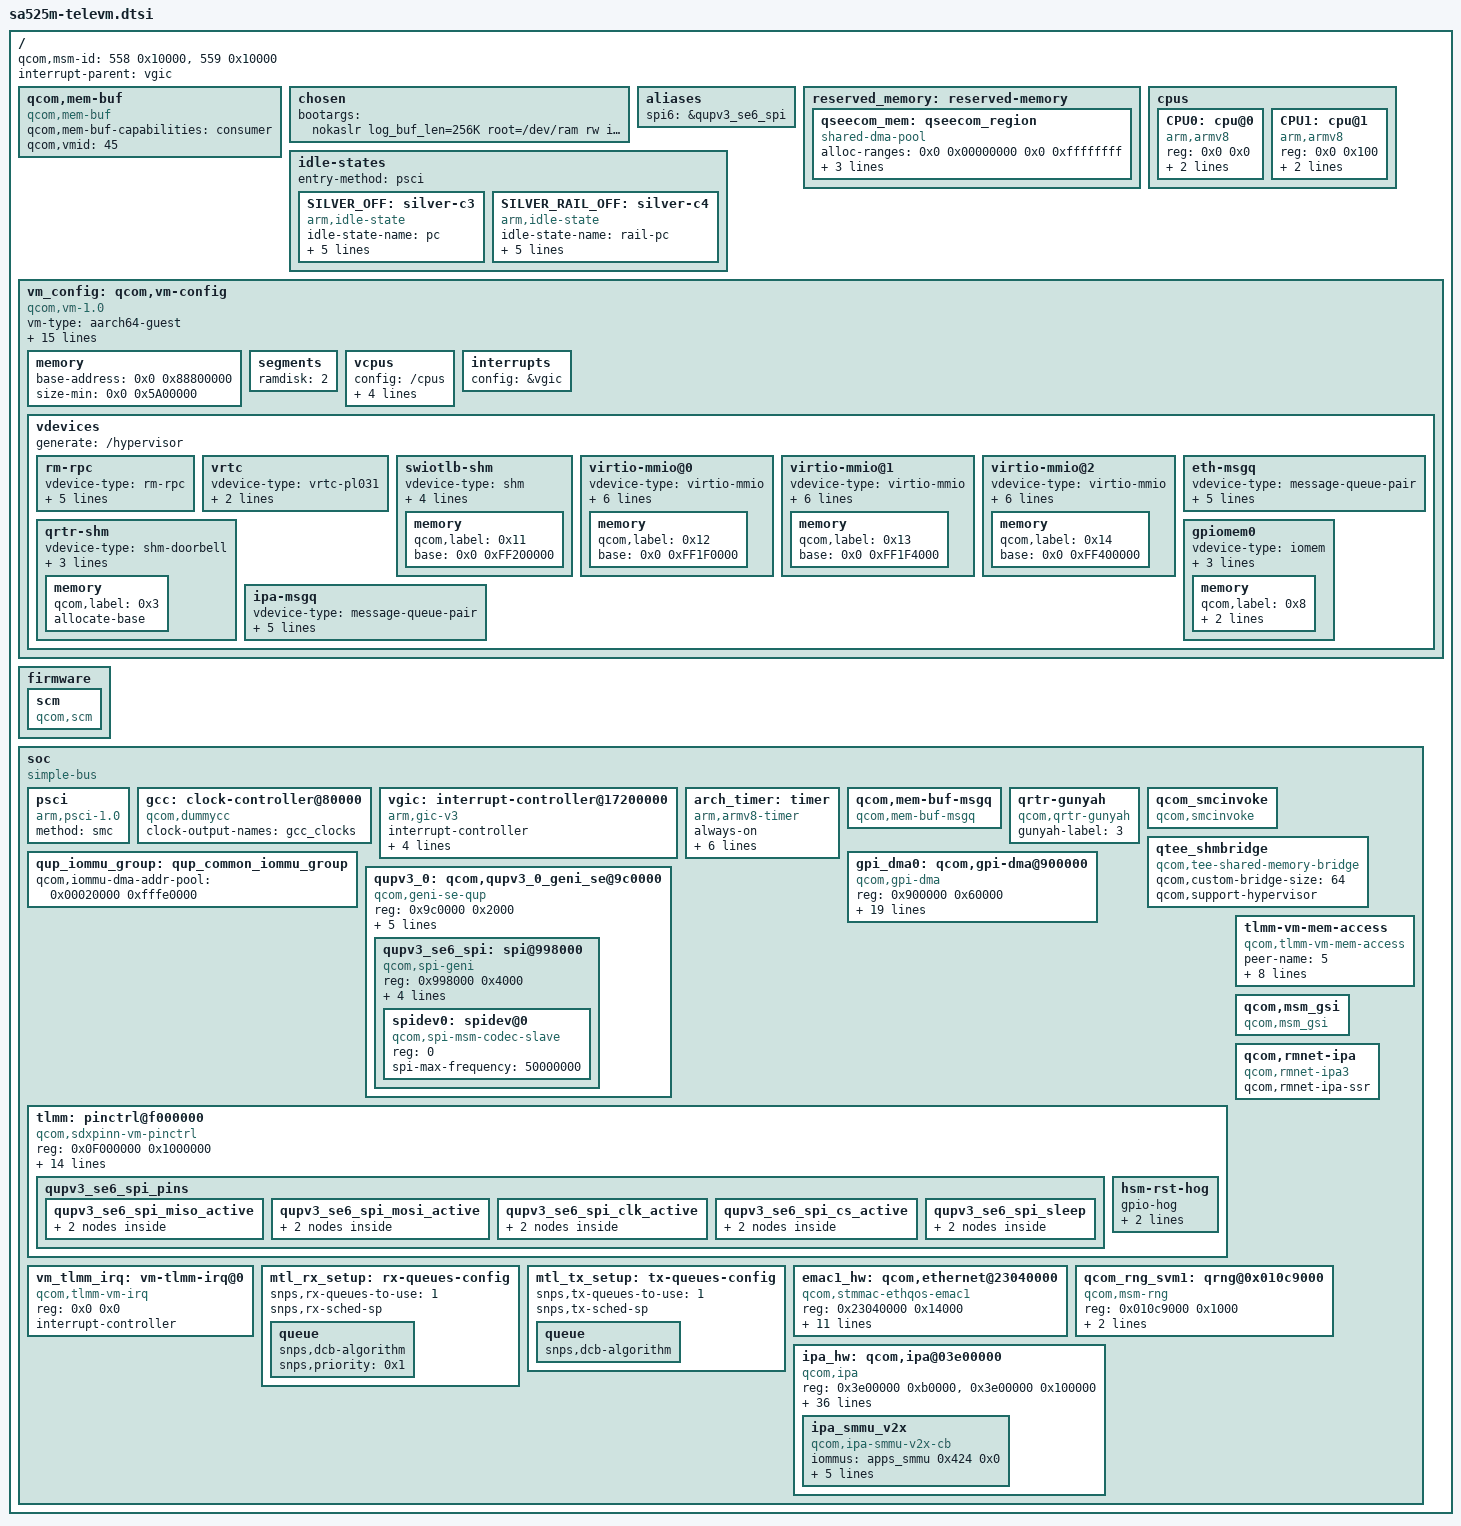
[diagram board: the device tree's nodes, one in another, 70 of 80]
#include <dt-bindings/interrupt-controller/arm-gic.h>
#include <dt-bindings/clock/qcom,gcc-sdxpinn.h>
#include <dt-bindings/clock/qcom,rpmh.h>

/ {
	#address-cells = <0x2>;
	#size-cells = <0x2>;
	qcom,msm-id = <558 0x10000>, <559 0x10000>;
	interrupt-parent = <&vgic>;

	qcom,mem-buf {
		compatible = "qcom,mem-buf";
		qcom,mem-buf-capabilities = "consumer";
		qcom,vmid = <45>;
	};

	chosen {
		 bootargs = "nokaslr log_buf_len=256K root=/dev/ram rw init=/init console=hvc0 loglevel=8";
	};

	aliases {
		spi6 = &qupv3_se6_spi;
	};

	reserved_memory: reserved-memory {
		#address-cells = <2>;
		#size-cells = <2>;
		ranges;
		qseecom_mem: qseecom_region {
			compatible = "shared-dma-pool";
			alloc-ranges = <0x0 0x00000000 0x0 0xffffffff>;
			reusable;
			alignment = <0x0 0x400000>;
			size = <0x0 0x400000>;
		};
	};

	cpus {
		#address-cells = <0x2>;
		#size-cells = <0x0>;

		CPU0: cpu@0 {
			compatible = "arm,armv8";
			reg = <0x0 0x0>;
			device_type = "cpu";
			enable-method = "psci";
			cpu-idle-states = <&SILVER_OFF &SILVER_RAIL_OFF>;
		};

		CPU1: cpu@1 {
			compatible = "arm,armv8";
			reg = <0x0 0x100>;
			device_type = "cpu";
			enable-method = "psci";
			cpu-idle-states = <&SILVER_OFF &SILVER_RAIL_OFF>;
		};

	};

	idle-states {
		entry-method = "psci";

		SILVER_OFF: silver-c3 { /* C3 */
			compatible = "arm,idle-state";
			idle-state-name = "pc";
			entry-latency-us = <235>;
			exit-latency-us = <428>;
			min-residency-us = <1774>;
			arm,psci-suspend-param = <0x40000003>;
			local-timer-stop;
		};

		SILVER_RAIL_OFF: silver-c4 { /* C4 */
			compatible = "arm,idle-state";
			idle-state-name = "rail-pc";
			entry-latency-us = <800>;
			exit-latency-us = <750>;
			min-residency-us = <4090>;
			arm,psci-suspend-param = <0x40000004>;
			local-timer-stop;
		};
	};

	vm_config: qcom,vm-config {
		compatible = "qcom,vm-1.0";
		vm-type = "aarch64-guest";
		boot-config = "fdt,unified";
		os-type = "linux";
		kernel-entry-segment = "kernel";
		kernel-entry-offset = <0x0 0x0>;
		vendor = "QTI";
		image-name = "qcom,televm";
		qcom,pasid = <0x0 0x1c>;
		qcom,qtee-config-info = "p=57,77,78,7C,8F,97,159,199,47E,7F1;";
		qcom,secdomain-ids = <45>;
		qcom,primary-vm-index = <0>;

		iomemory-ranges = <0x0 0x928000 0x0 0x928000 0x0 0x4000 0x0
				   0x0 0x998000 0x0 0x998000 0x0 0x4000 0x0
				   0x0 0x3e00000 0x0 0x3e00000 0x0 0x200000 0x0
				   0x0 0x23052000 0x0 0x23052000 0x0 0x1000 0x0
				   0x0 0x2304C000 0x0 0x2304C000 0x0 0x1000 0x0
				   0x0 0x0F1B7000 0x0 0x0F1B7000 0x0 0x2000 0x0
				   0x0 0x010c9000 0x0 0x010c9000 0x0 0x1000 0x0>;

		gic-irq-ranges = <245 245 // 213 DIR CONN HMMS /* PVM->SVM IRQ transfer */
				246 246 // 214 DIR CONN HMMS
				247 247 // 215 DIR CONN HMMS
				248 248 // 216 DIR CONN HMMS
				249 249 // 217 DIR CONN HMMS
				250 250 // 218 DIR CONN HMMS
				251 251 // 219 DIR CONN HMMS
				252 252 // 220 DIR CONN HMMS
				344 344 // 312 IPA
				350 350 // 318 IPA
				383 383 // 351 QUPV3 GSI IRQ
				432 432 // 400 MVM
				433 433 // 401 MVM
				436 436 // 404 MVM
				439 439 // 407 MVM
				483 483>;

		memory {
			#address-cells = <0x2>;
			#size-cells = <0x0>;
			base-address = <0x0 0x88800000>;
			size-min = <0x0 0x5A00000>; /* 90 MB */
		};

		segments {
			ramdisk = <2>; /* 8 MB */
		};

		vcpus {
			config = "/cpus";
			affinity = "proxy";
			affinity-map = <0x0 0x1>;
			sched-priority = <0>;       /* relative to PVM */
			sched-timeslice = <2000>;   /* in ms */
		};

		interrupts {
			config = &vgic;
		};

		vdevices {
			generate = "/hypervisor";
			rm-rpc {
				vdevice-type = "rm-rpc";
				generate = "/hypervisor/qcom,resource-mgr";
				console-dev;
				message-size = <0x000000f0>;
				queue-depth = <0x00000008>;
				qcom,label = <0x1>;
			};

			vrtc {
				vdevice-type = "vrtc-pl031";
				peer-default;
				allocate-base;
			};

			swiotlb-shm {
				vdevice-type = "shm";
				generate = "/swiotlb";
				push-compatible = "swiotlb";
				peer-default;
				dma_base = <0x0 0x10000>;
				memory {
					qcom,label = <0x11>;
					#address-cells = <0x2>;
					base = <0x0 0xFF200000>; /*2MB aligned*/

				};
			};

			virtio-mmio@0 {
				vdevice-type = "virtio-mmio";
				generate = "/virtio-mmio";
				peer-default;
				vqs-num = <0x1>;
				push-compatible = "virtio,mmio";
				dma-coherent;
				dma_base = <0x0 0x0>;
				memory {
					qcom,label = <0x12>;	//for systemrw.img
					#address-cells = <0x2>;
					base = <0x0 0xFF1F0000>;
				};
			};

			virtio-mmio@1 {
				vdevice-type = "virtio-mmio";
				generate = "/virtio-mmio";
				peer-default;
				vqs-num = <0x3>;
				push-compatible = "virtio,mmio";
				dma-coherent;
				dma_base = <0x0 0x4000>;
				memory {
					qcom,label = <0x13>;	//for net
					#address-cells = <0x2>;
					base = <0x0 0xFF1F4000>;
				};
			};

			virtio-mmio@2 {
				vdevice-type = "virtio-mmio";
				generate = "/virtio-mmio";
				peer-default;
				vqs-num = <0x2>;
				push-compatible = "virtio,mmio";
				dma-coherent;
				dma_base = <0x0 0x210000>;
				memory {
					qcom,label = <0x14>;	//for system.img
					#address-cells = <0x2>;
					base = <0x0 0xFF400000>;
				};
			};

			eth-msgq {
				vdevice-type = "message-queue-pair";
				generate = "/hypervisor/geth-msgq-pair";
				message-size = <0xf0>;
				queue-depth = <0x8>;
				peer-default;
				qcom,label = <0xB>;
			};

			qrtr-shm {
				vdevice-type = "shm-doorbell";
				generate = "/hypervisor/qrtr-shm";
				push-compatible = "qcom,qrtr-gunyah-gen";
				peer-default;
				memory {
					qcom,label = <0x3>;
					allocate-base;
				};
			};

			gpiomem0 {
				vdevice-type = "iomem";
				patch = "/soc/tlmm-vm-mem-access";
				push-compatible = "qcom,tlmm-vm-mem-access";
				peer-default;
				memory {
					qcom,label = <0x8>;
					qcom,mem-info-tag = <0x3>;
					allocate-base;
				};
			};

			ipa-msgq {
				vdevice-type = "message-queue-pair";
				generate = "/hypervisor/ipa-msgq-pair";
				message-size = <0xf0>;
				queue-depth = <0x8>;
				peer-default;
				qcom,label = <10>;
			};
		};
	};

	firmware: firmware {
		scm {
			compatible = "qcom,scm";
		};
	};

	soc: soc { };
};

&soc {
	#address-cells = <1>;
	#size-cells = <1>;
	ranges = <0 0 0 0xffffffff>;
	compatible = "simple-bus";

	psci {
		compatible = "arm,psci-1.0";
		method = "smc";
	};

	gcc: clock-controller@80000 {
		compatible = "qcom,dummycc";
		clock-output-names = "gcc_clocks";
		#clock-cells = <1>;
		#reset-cells = <1>;
	};

	vgic: interrupt-controller@17200000 {
		compatible = "arm,gic-v3";
		#interrupt-cells = <3>;
		interrupt-controller;
		#redistributor-regions = <1>;
		redistributor-stride = <0x0 0x20000>;
		reg = <0x17200000 0x10000>,/* GICD */
				<0x17260000 0x80000>;/* GICR * 4 */
		interrupts = <GIC_PPI 9 IRQ_TYPE_LEVEL_HIGH>;
	};

	arch_timer: timer {
		compatible = "arm,armv8-timer";
		always-on;
		interrupts = <GIC_PPI 13 (GIC_CPU_MASK_SIMPLE(8) | IRQ_TYPE_LEVEL_LOW)>,
			<GIC_PPI 14 (GIC_CPU_MASK_SIMPLE(8) | IRQ_TYPE_LEVEL_LOW)>,
			<GIC_PPI 11 (GIC_CPU_MASK_SIMPLE(8) | IRQ_TYPE_LEVEL_LOW)>,
			<GIC_PPI 12 (GIC_CPU_MASK_SIMPLE(8) | IRQ_TYPE_LEVEL_LOW)>;
		clock-frequency = <19200000>;

	};

	qcom,mem-buf-msgq {
		compatible = "qcom,mem-buf-msgq";
	};

	qrtr-gunyah {
		compatible = "qcom,qrtr-gunyah";
		gunyah-label = <3>;
	};

	qcom_smcinvoke {
		compatible = "qcom,smcinvoke";
	};

	 qtee_shmbridge {
		compatible = "qcom,tee-shared-memory-bridge";
		qcom,custom-bridge-size = <64>;
		qcom,support-hypervisor;
	};
	qup_iommu_group: qup_common_iommu_group {
		qcom,iommu-dma-addr-pool = <0x00020000 0xfffe0000>;
	};

	 /* GPI Instance */
	gpi_dma0: qcom,gpi-dma@900000  {
		compatible = "qcom,gpi-dma";
		#dma-cells = <5>;
		reg = <0x900000  0x60000>;
		reg-names = "gpi-top";
		iommus = <&apps_smmu 0xf8 0x0>;
		qcom,max-num-gpii = <12>;
		interrupts = <GIC_SPI 345 IRQ_TYPE_LEVEL_HIGH>,
			<GIC_SPI 346 IRQ_TYPE_LEVEL_HIGH>,
			<GIC_SPI 347 IRQ_TYPE_LEVEL_HIGH>,
			<GIC_SPI 348 IRQ_TYPE_LEVEL_HIGH>,
			<GIC_SPI 349 IRQ_TYPE_LEVEL_HIGH>,
			<GIC_SPI 350 IRQ_TYPE_LEVEL_HIGH>,
			<GIC_SPI 351 IRQ_TYPE_LEVEL_HIGH>,
			<GIC_SPI 352 IRQ_TYPE_LEVEL_HIGH>,
			<GIC_SPI 353 IRQ_TYPE_LEVEL_HIGH>,
			<GIC_SPI 354 IRQ_TYPE_LEVEL_HIGH>,
			<GIC_SPI 355 IRQ_TYPE_LEVEL_HIGH>,
			<GIC_SPI 356 IRQ_TYPE_LEVEL_HIGH>;
		qcom,gpii-mask = <0x40>;
		qcom,iommu-group = <&qup_iommu_group>;
		qcom,ev-factor = <2>;
		qcom,gpi-ee-offset = <0x10000>;
		dma-coherent;
		status = "ok";
	};

	/* QUPv3_0 wrapper instance */
	qupv3_0: qcom,qupv3_0_geni_se@9c0000 {
		compatible = "qcom,geni-se-qup";
		reg = <0x9c0000 0x2000>;
		#address-cells = <1>;
		#size-cells = <1>;
		clock-names = "m-ahb", "s-ahb";
		clocks = <&gcc GCC_QUPV3_WRAP_0_M_AHB_CLK>,
			<&gcc GCC_QUPV3_WRAP_0_S_AHB_CLK>;
		iommus = <&apps_smmu 0xf8 0x0>;
		qcom,iommu-group = <&qup_iommu_group>;
		dma-coherent;
		ranges;
		status = "ok";

		qupv3_se6_spi: spi@998000 {
			compatible = "qcom,spi-geni";
			reg = <0x998000 0x4000>;
			reg-names = "se_phys";
			#address-cells = <1>;
			#size-cells = <0>;
			dmas = <&gpi_dma0 0 6 1 64 0>,
				<&gpi_dma0 1 6 1 64 0>;
			dma-names = "tx", "rx";
			spi-max-frequency = <50000000>;
			qcom,le-vm;
			qcom,vm-no-pm;
			status = "disabled";
		};

	};

	pinctrl@f000000 {
		qupv3_se6_spi_pins: qupv3_se6_spi_pins {
			qupv3_se6_spi_miso_active: qupv3_se6_spi_miso_active {
				mux {
					pins = "gpio112";
					function = "qup_se6_l0";
				};

				config {
					pins = "gpio112";
					drive-strength = <6>;
					bias-pull-down;
				};
			};

			qupv3_se6_spi_mosi_active: qupv3_se6_spi_mosi_active {
				mux {
					pins = "gpio113";
					function = "qup_se6_l1";
				};

				config {
					pins = "gpio113";
					drive-strength = <6>;
					bias-pull-down;
				};
			};

			qupv3_se6_spi_clk_active: qupv3_se6_spi_clk_active {
				mux {
					pins = "gpio114";
					function = "qup_se6_l2";
				};

				config {
					pins = "gpio114";
					drive-strength = <6>;
					bias-pull-down;
				};
			};

			qupv3_se6_spi_cs_active: qupv3_se6_spi_cs_active {
				mux {
					pins = "gpio115";
					function = "qup_se6_l3";
				};

				config {
					pins = "gpio115";
					drive-strength = <6>;
					bias-pull-down;
				};
			};

			qupv3_se6_spi_sleep: qupv3_se6_spi_sleep {
				mux {
					pins = "gpio112", "gpio113",
						"gpio114", "gpio115";
					function = "gpio";
				};

				config {
					pins = "gpio112", "gpio113",
						"gpio114", "gpio115";
					drive-strength = <2>;
					bias-pull-down;
				};
			};
		};
	};


	vm_tlmm_irq: vm-tlmm-irq@0 {
		compatible = "qcom,tlmm-vm-irq";
		reg = <0x0 0x0>;
		interrupt-controller;
		#interrupt-cells = <2>;
	};

	tlmm: pinctrl@f000000 {
		compatible = "qcom,sdxpinn-vm-pinctrl";
		reg = <0x0F000000 0x1000000>;
		interrupts-extended = <&vm_tlmm_irq 1 IRQ_TYPE_LEVEL_HIGH>;
		gpio-controller;
		#gpio-cells = <2>;
		interrupt-controller;
		#interrupt-cells = <2>;
		interrupts = <GIC_SPI 212 IRQ_TYPE_LEVEL_HIGH>,
					<GIC_SPI 213 IRQ_TYPE_LEVEL_HIGH>,
					<GIC_SPI 214 IRQ_TYPE_LEVEL_HIGH>,
					<GIC_SPI 215 IRQ_TYPE_LEVEL_HIGH>,
					<GIC_SPI 216 IRQ_TYPE_LEVEL_HIGH>,
					<GIC_SPI 217 IRQ_TYPE_LEVEL_HIGH>,
					<GIC_SPI 218 IRQ_TYPE_LEVEL_HIGH>,
					<GIC_SPI 219 IRQ_TYPE_LEVEL_HIGH>,
					<GIC_SPI 220 IRQ_TYPE_LEVEL_HIGH>;
		/* Valid pins */
		gpios = /bits/ 16 <102 112 113 114 115>;
	};

	tlmm-vm-mem-access {
		compatible = "qcom,tlmm-vm-mem-access";
		peer-name = <5>; /* 5 => Televm */
		tlmm-vm-gpio-lend-list = <&tlmm 102 0 &tlmm 112 0 &tlmm 113 0 &tlmm 114 0 &tlmm 115 0>;
		pinctrl-names = "active", "sleep";
		pinctrl-0 = <&qupv3_se6_spi_mosi_active>, <&qupv3_se6_spi_miso_active>,
			<&qupv3_se6_spi_clk_active>, <&qupv3_se6_spi_cs_active>;
		pinctrl-1 = <&qupv3_se6_spi_sleep>;
	};

	mtl_rx_setup: rx-queues-config {
		snps,rx-queues-to-use = <1>;
		snps,rx-sched-sp;

		queue {
			snps,dcb-algorithm;
			snps,priority = <0x1>;
		};
	};

	mtl_tx_setup: tx-queues-config {
		snps,tx-queues-to-use = <1>;
		snps,tx-sched-sp;

		queue {
			snps,dcb-algorithm;
		};
	};

	emac1_hw: qcom,ethernet@23040000 {
		compatible = "qcom,stmmac-ethqos-emac1";

		reg = <0x23040000 0x14000>;
		reg-names = "stmmaceth";

		interrupts-extended = <&vgic 0 451 1>;
		interrupt-names = "tx_rx_ch4_intr";

		iommus = <&apps_smmu 0x45 0x0>,
			<&apps_smmu 0x4D 0x0>;
		qcom,iommu-dma-addr-pool = <0x80000000 0x40000000>;

		snps,tso;
		snps,pbl = <32>;
		rx-fifo-depth = <4096>;
		tx-fifo-depth = <4096>;
		snps,mtl-rx-config = <&mtl_rx_setup>;
		snps,mtl-tx-config = <&mtl_tx_setup>;
		queue = <4>;
	};

	qcom,msm_gsi {
		compatible = "qcom,msm_gsi";
	};

	qcom,rmnet-ipa {
		compatible = "qcom,rmnet-ipa3";
		qcom,rmnet-ipa-ssr;
	};

	qcom_rng_svm1: qrng@0x010c9000 {
		compatible = "qcom,msm-rng";
		reg = <0x010c9000 0x1000>;
		qcom,no-qrng-config;
		qcom,no-clock-support;
	};

	ipa_hw: qcom,ipa@03e00000 {
		compatible = "qcom,ipa";
		reg =
			<0x3e00000 0xb0000>,
			<0x3e00000 0x100000>;
		reg-names = "ipa-base", "gsi-base";
		qcom,ipa-cfg-offset = <0x0114000>;
		interrupts =
			<0 318 IRQ_TYPE_LEVEL_HIGH>,
			<0 312 IRQ_TYPE_LEVEL_HIGH>;
		interrupt-names = "ipa-irq", "gsi-irq";
		qcom,ipa-hw-ver = <25>; /* IPA core version = IPAv6.0 */
		qcom,ipa-hw-mode = <0>; // IPA_HW_MODE_NORMAL
		qcom,platform-type = <0>; /* MDM platform */
		qcom,ee = <4>; /* V2X EE */
		qcom,entire-ipa-block-size = <0x200000>;
		qcom,ipa-v2x-vm;
		qcom,use-ipa-tethering-bridge;
		qcom,use-tput-estmation-pipe;
		qcom,mhi-event-ring-id-limits = <9 15>;
		qcom,modem-cfg-emb-pipe-flt;
		qcom,use-xbl-boot;
		qcom,arm-smmu;
		qcom,smmu-fast-map;
		qcom,use-64-bit-dma-mask;
		qcom,ipa-wdi3-over-gsi;
		qcom,ipa-wdi3-holb-2g = <15>;
		qcom,ipa-wdi3-holb-5g = <31>;
		qcom,ipa-endp-delay-wa-v2;
		qcom,tx-wrapper-cache-max-size = <400>;
		qcom,ipa-gpi-event-rp-ddr;
		qcom,ulso-supported;
		qcom,ulso-ip-id-min-linux-val = <0>;
		qcom,ulso-ip-id-max-linux-val = <0xffff>;
		qcom,ulso-ip-id-min-windows-val = <0>;
		qcom,ulso-ip-id-max-windows-val = <0x7fff>;
		qcom,register-collection-on-crash;
		qcom,testbus-collection-on-crash;
		qcom,non-tn-collection-on-crash;
		qcom,interconnect,num-cases = <5>;
		qcom,interconnect,num-paths = <3>;
		qcom,max_num_smmu_cb = <1>;
		gunyah-label = <10>;
		qcom,ipa-config-is-auto;

		ipa_smmu_v2x: ipa_smmu_v2x {
			compatible = "qcom,ipa-smmu-v2x-cb";
			iommus = <&apps_smmu 0x424 0x0>;
			qcom,iommu-dma-addr-pool = <0x20000000 0x20000000>;
			qcom,iommu-geometry = <0x0 0xA0000000>;
			qcom,iommu-dma = "fastmap";
			dma-coherent;
		};
	};
};

&qupv3_se6_spi {
	status = "ok";
	spidev0: spidev@0 {
		compatible = "qcom,spi-msm-codec-slave";
		reg =<0>;
		spi-max-frequency = <50000000>;
	};
};

&tlmm {
	hsm-rst-hog {
		gpio-hog;
		gpios = <102 0>;
		output-high;
	};
};

#include "msm-arm-smmu-sdxpinn-vm.dtsi"
#include "sdxpinn-vm-dma-heaps.dtsi"
